VERSION ""

NS_ :

BS_:

BU_: TEST_NODE TEST_NODE_2 DAQ

BO_ 2483029759 orion_currents_volts2: 4 TEST_NODE
 SG_ pack_voltage : 16|16@1+ (0.1,0) [0|0] "V" Vector__XXX
 SG_ pack_current : 0|16@1- (0.1,0) [0|0] "A" Vector__XXX

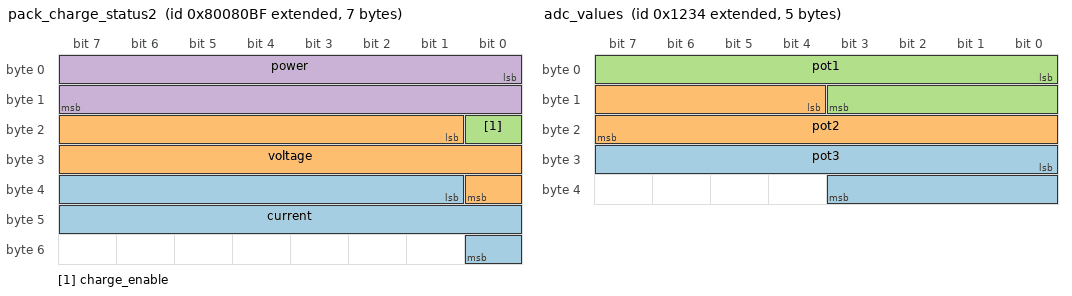
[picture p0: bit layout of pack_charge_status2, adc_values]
BO_ 2281734335 pack_charge_status2: 7 TEST_NODE
 SG_ current : 33|16@1+ (0.1,0) [0|0] "A" Vector__XXX
 SG_ voltage : 17|16@1+ (0.1,0) [0|0] "V" Vector__XXX
 SG_ charge_enable : 16|1@1+ (1,0) [0|0] "" Vector__XXX
 SG_ power : 0|16@1+ (1,0) [0|0] "W" Vector__XXX

BO_ 2483028095 test_msg: 2 TEST_NODE
 SG_ test_sig : 0|16@1- (1,0) [0|0] "" Vector__XXX

BO_ 2483028159 test_msg2: 2 TEST_NODE
 SG_ test_sig2 : 0|16@1+ (1,0) [0|0] "" Vector__XXX

BO_ 2483028223 test_msg3: 2 TEST_NODE
 SG_ test_sig3 : 0|16@1+ (1,0) [0|0] "" Vector__XXX

BO_ 2483028287 test_msg4: 2 TEST_NODE
 SG_ test_sig4 : 0|16@1+ (1,0) [0|0] "" Vector__XXX

BO_ 2483028351 test_msg5: 2 TEST_NODE
 SG_ test_sig5 : 0|16@1+ (1,0) [0|0] "" Vector__XXX

BO_ 2348810751 wheel_speeds: 8 TEST_NODE
 SG_ right_speed : 32|32@1- (1,0) [0|0] "kph" Vector__XXX
 SG_ left_speed : 0|32@1- (1,0) [0|0] "kph" Vector__XXX

BO_ 2147488308 adc_values: 5 TEST_NODE
 SG_ pot3 : 24|12@1+ (1,0) [0|0] "" Vector__XXX
 SG_ pot2 : 12|12@1+ (1,0) [0|0] "" Vector__XXX
 SG_ pot1 : 0|12@1+ (1,0) [0|0] "" Vector__XXX

BO_ 2347693088 car_state: 1 TEST_NODE
 SG_ car_state : 0|8@1+ (1,0) [0|0] "" Vector__XXX

BO_ 2148060031 fault_sync_test_node: 3 TEST_NODE
 SG_ latched : 16|1@1+ (1,0) [0|0] "" Vector__XXX
 SG_ idx : 0|16@1+ (1,0) [0|0] "" Vector__XXX

BO_ 2550136831 daq_response_TEST_NODE_TEST: 8 TEST_NODE
 SG_ daq_response : 0|64@1+ (1,0) [0|0] "" Vector__XXX

BO_ 2483028093 test_msg_2: 2 TEST_NODE_2
 SG_ test_sig : 0|16@1+ (1,0) [0|0] "" Vector__XXX

BO_ 2483028157 test_msg2_2: 2 TEST_NODE_2
 SG_ test_sig2 : 0|16@1+ (1,0) [0|0] "" Vector__XXX

BO_ 2483028221 test_msg3_2: 2 TEST_NODE_2
 SG_ test_sig3 : 0|16@1+ (1,0) [0|0] "" Vector__XXX

BO_ 2483028285 test_msg4_2: 2 TEST_NODE_2
 SG_ test_sig4 : 0|16@1+ (1,0) [0|0] "" Vector__XXX

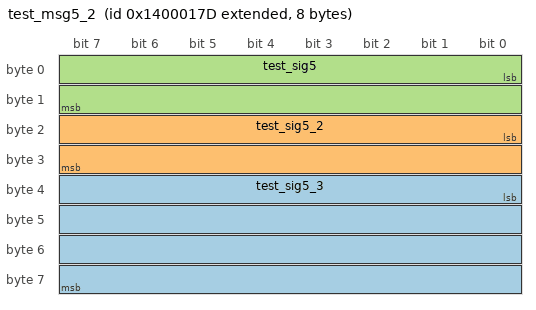
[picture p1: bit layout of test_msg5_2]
BO_ 2483028349 test_msg5_2: 8 TEST_NODE_2
 SG_ test_sig5_3 : 32|32@1- (1,0) [0|0] "" Vector__XXX
 SG_ test_sig5_2 : 16|16@1- (1,0) [0|0] "" Vector__XXX
 SG_ test_sig5 : 0|16@1+ (1,0) [0|0] "" Vector__XXX

BO_ 2147492386 test_stale: 1 TEST_NODE_2
 SG_ data : 0|8@1+ (1,0) [0|0] "" Vector__XXX

BO_ 2347693089 car_state2: 1 TEST_NODE_2
 SG_ car_state2 : 0|8@1+ (1,0) [0|0] "" Vector__XXX

BO_ 2483032050 daq_command_TEST_NODE_TEST: 8 DAQ
 SG_ daq_command : 0|64@1+ (1,0) [0|0] "" Vector__XXX

CM_ BO_ 2483029759 "Pack current + voltage";
CM_ BO_ 2281734335 "Send charge information";
CM_ SG_ 2281734335 current "Instantaneous charge current";
CM_ SG_ 2281734335 voltage "Instantaneous charge voltage";
CM_ SG_ 2281734335 charge_enable "Charge mode enable";
CM_ SG_ 2281734335 power "Instantaneous charge power";
CM_ BO_ 2483028095 "test_msg desc";
CM_ BO_ 2483028159 "test_msg2 desc";
CM_ BO_ 2483028223 "test_msg2 desc";
CM_ BO_ 2483028287 "test_msg4 desc";
CM_ BO_ 2483028351 "test_msg5 desc";
CM_ BO_ 2348810751 "wheel speeds";
CM_ BO_ 2147488308 "adc potentiometer readings";
CM_ BO_ 2347693088 "state of the car";
CM_ BO_ 2148060031 "Fault status message";
CM_ BO_ 2550136831 "daq response from node TEST_NODE";
CM_ BO_ 2483028093 "test_msg desc";
CM_ BO_ 2483028157 "test_msg2 desc";
CM_ BO_ 2483028221 "test_msg2 desc";
CM_ BO_ 2483028285 "test_msg4 desc";
CM_ BO_ 2483028349 "test_msg5 desc";
CM_ BO_ 2147492386 "used to test stale";
CM_ BO_ 2347693089 "state of the car";
CM_ BO_ 2483032050 "daq command for node TEST_NODE_TEST";

VAL_ 2347693088 car_state 0 "ready2go" 1 "flipped" 2 "flying" 3 "lightspeed" ;
VAL_ 2347693089 car_state2 0 "ready2go" 1 "flipped" 2 "flying" 3 "lightspeed" ;
SIG_VALTYPE_ 2348810751 left_speed : 1;
SIG_VALTYPE_ 2348810751 right_speed : 1;
SIG_VALTYPE_ 2483028349 test_sig5_3 : 1;
